# CC2340R5 register map
File version: 1.0
CPU: CM0P 1.0, other endian, MPU, FPU, 3 interrupt priority bits
Registers are 32-bit, read-write, reset 0x0 unless marked. A register's access mark holds for its fields unless they carry their own. Offsets are from the block's base; [hi:lo] are bit positions; lines under a group give offsets from that group; {n}, {i} and the like mark numbered series; 'fields as' and 'values as' point back to an identical list.

## IOC — ULL IOC
Base 0x40003000
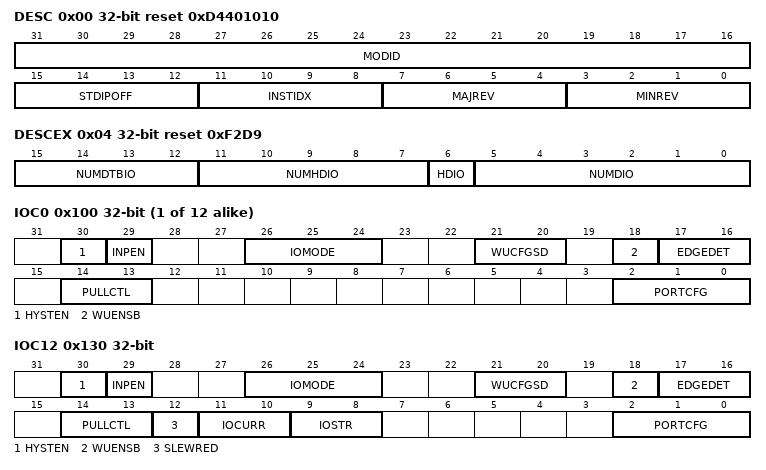
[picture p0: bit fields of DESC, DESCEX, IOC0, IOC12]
0x00 DESC reset 0xD4401010 — Description Register. This register provides IP module ID, revision information, instance index and standard MMR registers offset.
  [31:16] MODID — [31:16] Module identifier used to uniquely identify this IP.
  [15:12] STDIPOFF — [15:12] Standard IP MMR block offset. Standard IP MMRs are the set of from aggregated IRQ registers till DTB. 0: Standard IP MMRs do not exist 0x1-0xF: Standard IP MMRs begin at offset of (64*STDIPOFF from the base IP address)
  [11:8] INSTIDX — [11:8] IP Instance ID number. If multiple instances of IP exist in the device, this field can identify the instance number (0-15).
  [7:4] MAJREV — [7:4] Major revision of IP (0-15).
  [3:0] MINREV — [3:0] Minor revision of IP (0-15).
0x04 DESCEX reset 0xF2D9 — Extended Description Register. This register provides configuration details of the IP to software drivers and end users.
  [15:12] NUMDTBIO — [15:12] Number of DTB IOs supported. Total DTB IOs supported is NUMDTBIO value +1.
    15=MAXIMUM (Highest possible value); 0=MINIMUM (Smallest value)
  [11:7] NUMHDIO — [11:7] Number of HD IOs supported. Total HD IOs supported is NUMHDIO value +1.
    31=MAXIMUM (Highest possible value); 0=MINIMUM (Smallest value)
  [6] HDIO — [6:6] High drive IO supported by IOC.
    1=PRESENT (HD IO supported by IOC); 0=ABSENT (HD IO not supported by IOC)
  [5:0] NUMDIO — [5:0] Number of DIOs supported. Total DIOs supported is NUMDIO value +1.
    63=MAXIMUM (Highest possible value); 0=MINIMUM (Smallest value)
0x64 DTB — Digital Test Bus. This register is used to bring out some internal signals of the peripheral on digital test bus (DTB).
  [2:0] SEL — [2:0] Digital test bus selection mux control. Non-zero select values output a 16 bit selected group of signals per value.
    0=DIS (DTB output from peripheral is 0x0)
{0x100+4i} IOC{i} (i=0..11) — Configuration of DIO{i}
  [30] HYSTEN — [30:30] This field controls input hysteresis
    1=EN (Input hysteresis enabled); 0=DIS (Input hysteresis disabled)
  [29] INPEN — [29:29] Input enable
    1=EN (Input enabled); 0=DIS (Input disabled)
  [26:24] IOMODE — [26:24] IO Mode. Setting this to value 0x6 or 0x7 will default to normal IO behavior.
    5=OPENS_INV (Open Source, inverted IO); 4=OPENS (Open Source, normal IO); 3=OPEND_INV (Open Drain, inverted IO); 2=OPEND (Open Drain, normal IO); 1=INVERTED (Inverted IO); 0=NORMAL (Normal IO)
  [21:20] WUCFGSD — [21:20] Wakeup configuration from shutdown
    3=WAKE_HIGH (Wakeup triggered when pad level is high); 2=WAKE_LOW (Wakeup triggered when pad level is low); 1=DIS_1 (Wakeup disabled); 0=DIS_0 (Wakeup disabled)
  [18] WUENSB — [18:18] Wakeup enable from standby
    1=EN (wakeup enabled (effective only if EDGEDET is enabled)); 0=DIS (Wakeup disabled)
  [17:16] EDGEDET — [17:16] Edge detect configuration
    3=EDGE_BOTH (Positive and negative edge detection); 2=EDGE_POS (Positive edge detection); 1=EDGE_NEG (Negative edge detection); 0=EDGE_DIS (No edge detection)
  [14:13] PULLCTL — [14:13] Pull control. Setting this to value 0x3 disables pull.
    2=PULL_UP (Pull up enabled); 1=PULL_DOWN (Pull down enabled); 0=PULL_DIS (No pull)
  [2:0] PORTCFG — [2:0] Port configuration.
    7=DTB (Digital Test Bus function); 6=ANA (Analog function); {v}=PFUNC{v} (Digital peripheral function-{v}) (v=1..5); 0=BASE (Base function)
0x130 IOC12 — Configuration of DIO12
  [30] HYSTEN — [30:30] This field controls input hysteresis
    values as IOC0.HYSTEN
  [29] INPEN — [29:29] Input enable
    1=EN (Input enabled); 0=DIS (Input disabled)
  [26:24] IOMODE — [26:24] IO Mode. Setting this to value 0x6 or 0x7 will default to normal IO behavior.
    values as IOC0.IOMODE
  [21:20] WUCFGSD — [21:20] Wakeup configuration from shutdown
    values as IOC0.WUCFGSD
  [18] WUENSB — [18:18] Wakeup enable from standby
    values as IOC0.WUENSB
  [17:16] EDGEDET — [17:16] Edge detect configuration
    values as IOC0.EDGEDET
  [14:13] PULLCTL — [14:13] Pull control. Setting this to value 0x3 disables pull.
    values as IOC0.PULLCTL
  [12] SLEWRED — [12:12] Slew rate configuration
    1=REDUCED (Reduced slew rate); 0=NORMAL (Normal slew rate)
  [11:10] IOCURR — [11:10] Output current configuration. Writing value 0x3 defaults to 2mA current setting.
    2=CUR_8MA (8mA); 1=CUR_4MA (4mA); 0=CUR_2MA (2mA)
  [9:8] IOSTR — [9:8] Drive strength configuration
    3=MAX (Maximum drive strength); 2=MEDIUM (Medium drive strength); 1=MIN (Minimum drive stregnth); 0=AUTO (Automatic drive strength adjustment)
  [2:0] PORTCFG — [2:0] Port configuration.
    values as IOC0.PORTCFG
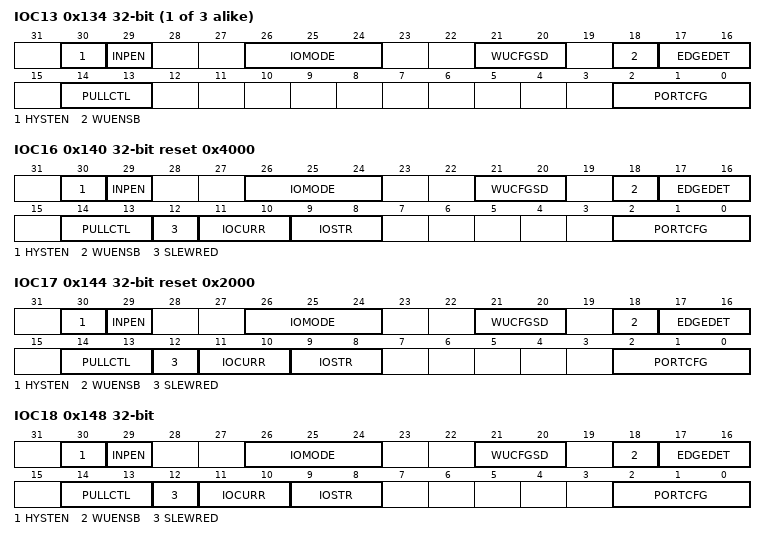
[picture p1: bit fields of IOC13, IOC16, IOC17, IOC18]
{0x100+4i} IOC{i} (i=13..15) — Configuration of DIO{i}
  fields as IOC0
0x140 IOC16 reset 0x4000 — Configuration of DIO16
  fields as IOC12
0x144 IOC17 reset 0x2000 — Configuration of DIO17
  fields as IOC12
0x148 IOC18 — Configuration of DIO18
  fields as IOC12
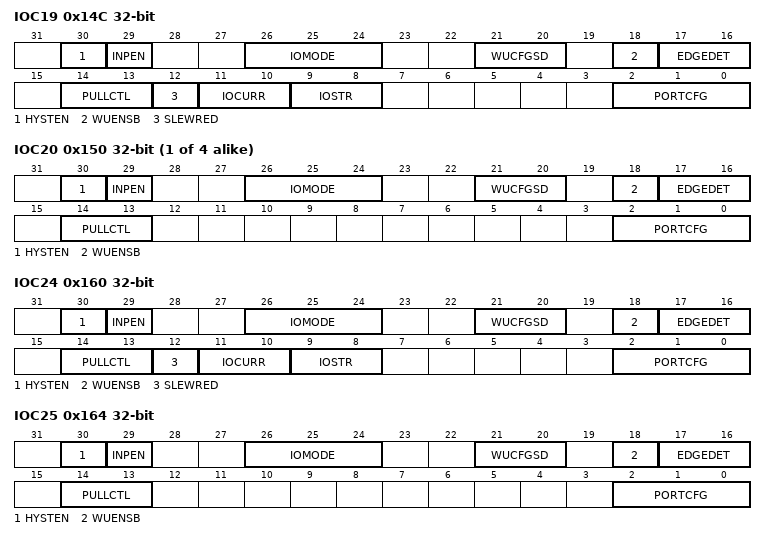
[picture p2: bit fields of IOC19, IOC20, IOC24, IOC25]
0x14C IOC19 — Configuration of DIO19
  fields as IOC12
{0x100+4i} IOC{i} (i=20..23) — Configuration of DIO{i}
  fields as IOC0
0x160 IOC24 — This field controls input hysteresis
  [30] HYSTEN — [30:30] Input hysteresis enable
    values as IOC0.HYSTEN
  [29] INPEN — [29:29] Input enable
    1=EN (Input enabled); 0=DIS (Input disabled)
  [26:24] IOMODE — [26:24] IO Mode. Setting this to value 0x6 or 0x7 will default to normal IO behavior.
    values as IOC0.IOMODE
  [21:20] WUCFGSD — [21:20] Wakeup configuration from shutdown
    values as IOC0.WUCFGSD
  [18] WUENSB — [18:18] Wakeup enable from standby
    values as IOC0.WUENSB
  [17:16] EDGEDET — [17:16] Edge detect configuration
    values as IOC0.EDGEDET
  [14:13] PULLCTL — [14:13] Pull control. Setting this to value 0x3 disables pull.
    values as IOC0.PULLCTL
  [12] SLEWRED — [12:12] Slew rate configuration
    1=REDUCED (Reduced slew rate); 0=NORMAL (Normal slew rate)
  [11:10] IOCURR — [11:10] Output current configuration. Writing value 0x3 defaults to 2mA current setting.
    2=CUR_8MA (8mA); 1=CUR_4MA (4mA); 0=CUR_2MA (2mA)
  [9:8] IOSTR — [9:8] Drive strength configuration
    values as IOC12.IOSTR
  [2:0] PORTCFG — [2:0] Port configuration.
    values as IOC0.PORTCFG
0x164 IOC25 — Configuration of DIO25
  fields as IOC0
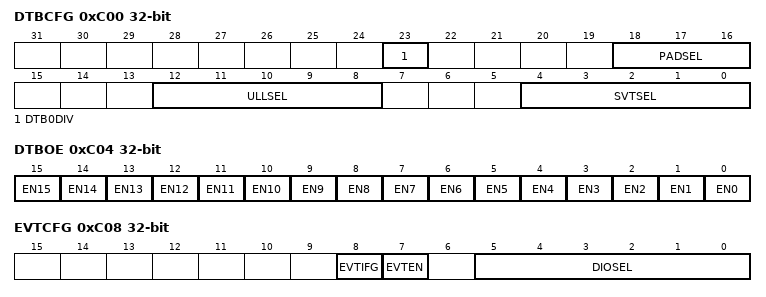
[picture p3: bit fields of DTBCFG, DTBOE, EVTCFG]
0xC00 DTBCFG — DTB configuration
  [23] DTB0DIV — [23:23] This bit is used to divide DTB[0] output by 8.
    1=EN (Divide DTB[0] output by 8); 0=DIS (No divide)
  [18:16] PADSEL — [18:16] Selects which 3 DTB lines out of total 16 are routed to DTB pins 15 to 13.
    5=DTB2TO0 (DTB[2:0] selected); 4=DTB5TO3 (DTB[5:3] selected); 3=DTB8TO6 (DTB[8:6] selected); 2=DTB11TO9 (DTB[11:9] selected); 1=DTB14TO12 (DTB[14:12] selected); 0=DTB15TO13 (DTB[15:13] selected)
  [12:8] ULLSEL — [12:8] ULL DTB Mux selection
    31=MAXIMUM (Maximum value); 0=MINIMUM (Minimum value)
  [4:0] SVTSEL — [4:0] SVT DTB Mux selection
    31=MAXIMUM (Maximum value); 0=MINIMUM (Minimum value)
0xC04 DTBOE — DTB output enable
  [all] fields
    1=EN (DTB output enabled); 0=DIS (DTB output disabled)
  [n] EN{n} (n=0..15) — [{n}:{n}] Enables DTB output {n}
0xC08 EVTCFG — Event configuration. This register is used to select DIO for IOC to publish event on AON event fabric. It also contains enable bit that is used to mask the event and event flag bit.
  [8] EVTIFG — [8:8] Event flag. It is set when edge is detected on selected DIO. Note: The edge detector flop is cleared for the selected DIO when EVTIFG is cleared by software.
    1=SET; 0=CLR (Clear)
  [7] EVTEN — [7:7] Enables IOC to publish event on AON event fabric when EVTIFG is set.
    1=EN (Enable); 0=DIS (Disable)
  [5:0] DIOSEL — [5:0] This is used to select DIO for event generation. For example, DIOSEL = 0x0 selects DIO0 and DIOSEL = 0x8 selects DIO8.
    63=MAXIMUM (Maximum value); 0=MINIMUM (Minimum value)
0xC0C TEST
  [0] SEL — [0:0] This is used to drive SWDIO (Serial Wire DIO) output data and output enable from debug sub-system onto DIO12 (Test Data Output) pad.
    1=HIGH (Output data and output enable driven based on debug sub-system inputs); 0=LOW (Output data and output enable managed by IOC)
0xC10 DTBSTAT — DTB status register.
  [15:0] VAL ro — [15:0] This bit field captures the final 16-bit value of DTB signals provided from IOC to DTB device pins.
